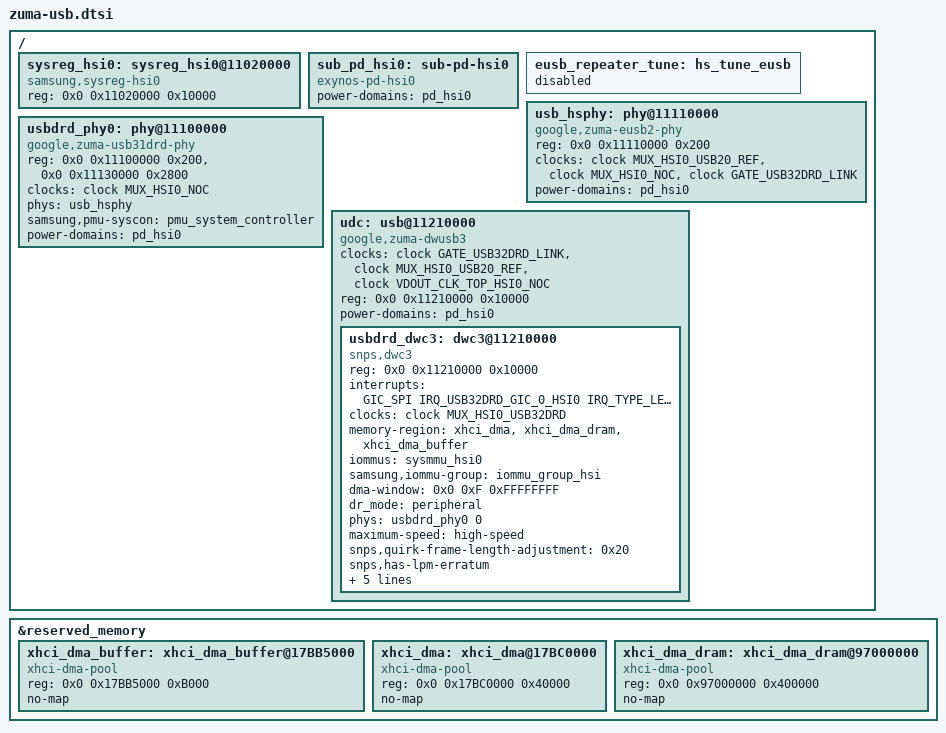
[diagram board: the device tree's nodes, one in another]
// SPDX-License-Identifier: GPL-2.0-only
/*
 * USB device tree source code for Zuma SoC
 *
 * Reworked to use the mainline Samsung/Synopsys USB drivers, modelled on
 * exynos2200: the high-speed side is a Synopsys eUSB2 PHY (phy-snps-eusb2)
 * reached as the "hs" sub-PHY of the USB3.1 DRD combo PHY (phy-exynos5-usbdrd),
 * which also brings up the Synopsys USBDP Gen2 V4 SuperSpeed lanes; the dwc3
 * core is glued by dwc3-exynos.
 *
 * Copyright 2022 Google LLC.
 */

#include <dt-bindings/interrupt-controller/zuma.h>
#include <dt-bindings/clock/zuma.h>

&reserved_memory {
	xhci_dma_buffer: xhci_dma_buffer@17BB5000 {
		compatible = "xhci-dma-pool";
		reg = <0x0 0x17BB5000 0xB000>;
		no-map;
	};

	xhci_dma: xhci_dma@17BC0000 {
		compatible = "xhci-dma-pool";
		reg = <0x0 0x17BC0000 0x40000>;
		no-map;
	};

	xhci_dma_dram: xhci_dma_dram@97000000 {
		compatible = "xhci-dma-pool";
		reg = <0x0 0x97000000 0x400000>;
		no-map;
	};
};

/ {
	sysreg_hsi0: sysreg_hsi0@11020000 {
		compatible = "samsung,sysreg-hsi0", "syscon";
		reg = <0x0 0x11020000 0x10000>;
	};

	sub_pd_hsi0: sub-pd-hsi0 {
		compatible = "exynos-pd-hsi0";
		power-domains = <&pd_hsi0>;
		status = "okay";
	};

	/*
	 * Legacy placeholder kept so sibling boards that still override
	 * &eusb_repeater_tune (with the old out-of-tree repeater binding)
	 * continue to resolve. The mainline repeater driver reads its tuning
	 * from the "samsung,tune-param" property on the repeater node instead.
	 */
	eusb_repeater_tune: hs_tune_eusb {
		status = "disabled";
	};

	/* Synopsys eUSB2 high-speed PHY ("hs" sub-PHY of the combo PHY). */
	usb_hsphy: phy@11110000 {
		compatible = "google,zuma-eusb2-phy";
		reg = <0x0 0x11110000 0x200>;
		clocks = <&clock MUX_HSI0_USB20_REF>,
			 <&clock MUX_HSI0_NOC>,
			 <&clock GATE_USB32DRD_LINK>;
		clock-names = "ref", "bus", "ctrl";
		#phy-cells = <0>;
		power-domains = <&pd_hsi0>;
		status = "okay";
	};

	/* USB3.1 DRD combo PHY: HS link + USBDP Gen2 V4 SuperSpeed. */
	usbdrd_phy0: phy@11100000 {
		compatible = "google,zuma-usb31drd-phy";
		reg = <0x0 0x11100000 0x200>,
		      <0x0 0x11130000 0x2800>;
		reg-names = "phy", "pma";
		/* HSI0 NOC bus clock gates register access (like exynos2200's "phy") */
		clocks = <&clock MUX_HSI0_NOC>;
		clock-names = "phy";
		#phy-cells = <1>;
		phys = <&usb_hsphy>;
		phy-names = "hs";
		samsung,pmu-syscon = <&pmu_system_controller>;
		power-domains = <&pd_hsi0>;
		status = "okay";
	};

	udc: usb@11210000 {
		compatible = "google,zuma-dwusb3";
		clocks = <&clock GATE_USB32DRD_LINK>,
			 <&clock MUX_HSI0_USB20_REF>,
			 <&clock VDOUT_CLK_TOP_HSI0_NOC>;
		clock-names = "link_aclk", "susp_clk", "bus_early";
		reg = <0x0 0x11210000 0x10000>;
		#address-cells = <2>;
		#size-cells = <1>;
		ranges;
		status = "okay";
		power-domains = <&pd_hsi0>;

		usbdrd_dwc3: dwc3@11210000 {
			compatible = "snps,dwc3";
			reg = <0x0 0x11210000 0x10000>;
			interrupts = <GIC_SPI IRQ_USB32DRD_GIC_0_HSI0 IRQ_TYPE_LEVEL_HIGH 0>;
			clocks = <&clock MUX_HSI0_USB32DRD>;
			clock-names = "ref";
			memory-region = <&xhci_dma>, <&xhci_dma_dram>, <&xhci_dma_buffer>;
			iommus = <&sysmmu_hsi0>;
			samsung,iommu-group = <&iommu_group_hsi>;

			/* Device virtual address */
			#dma-address-cells = <1>;
			#dma-size-cells = <2>;
			dma-window = <0x0 0xF 0xFFFFFFFF>;

			/*
			 * Force peripheral for bring-up so the gadget (adb)
			 * always enumerates without depending on the Type-C
			 * controller asserting device-role. Switch back to
			 * "otg" once host/role-switch is validated.
			 */
			dr_mode = "peripheral";
			/*
			 * HS-only for now: the combo PHY's SuperSpeed (USBDP
			 * Gen2 V4) PMA bring-up still needs a zuma-specific
			 * sequence. Only the eUSB2 "usb2-phy" is wired so the
			 * gadget enumerates at high-speed; re-add <&usbdrd_phy0 1>
			 * / "usb3-phy" and "super-speed-plus" once SS works.
			 */
			phys = <&usbdrd_phy0 0>;
			phy-names = "usb2-phy";

			maximum-speed = "high-speed";
			snps,quirk-frame-length-adjustment = <0x20>;
			snps,has-lpm-erratum;
			snps,lpm-nyet-threshold = <0>;
			snps,usb2-gadget-lpm-disable;
			snps,dis-u2-freeclk-exists-quirk;
			/* disabling U1/U2 speeds up NCM tethering by >2x */
			snps,dis-u1-entry-quirk;
			snps,dis-u2-entry-quirk;
		};
	};
};
